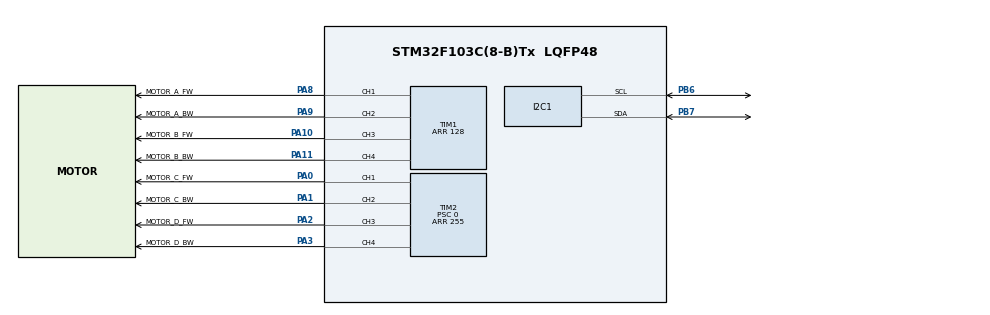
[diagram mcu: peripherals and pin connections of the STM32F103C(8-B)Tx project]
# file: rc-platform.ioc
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I2C1.GeneralCallMode=I2C_GENERALCALL_DISABLE
I2C1.OwnAddress=23
Mcu.Family=STM32F1
Mcu.Name=STM32F103C(8-B)Tx
Mcu.Package=LQFP48
NVIC.I2C1_EV_IRQn=true\:0\:0\:false\:false\:true\:true\:true\:true
NVIC.PriorityGroup=NVIC_PRIORITYGROUP_4
PA0-WKUP.GPIO_Label=MOTOR_C_FW
PA0-WKUP.Signal=S_TIM2_CH1_ETR
PA1.GPIO_Label=MOTOR_C_BW
PA1.Signal=S_TIM2_CH2
PA10.GPIO_Label=MOTOR_B_FW
PA10.Signal=S_TIM1_CH3
PA11.GPIO_Label=MOTOR_B_BW
PA11.Signal=S_TIM1_CH4
PA13.Mode=Serial_Wire
PA13.Signal=SYS_JTMS-SWDIO
PA14.Mode=Serial_Wire
PA14.Signal=SYS_JTCK-SWCLK
PA2.GPIO_Label=MOTOR_D_FW
PA2.Signal=S_TIM2_CH3
PA3.GPIO_Label=MOTOR_D_BW
PA3.Signal=S_TIM2_CH4
PA8.GPIO_Label=MOTOR_A_FW
PA8.Signal=S_TIM1_CH1
PA9.GPIO_Label=MOTOR_A_BW
PA9.Signal=S_TIM1_CH2
PB6.Mode=I2C
PB6.Signal=I2C1_SCL
PB7.Mode=I2C
PB7.Signal=I2C1_SDA
ProjectManager.HeapSize=0x200
ProjectManager.StackSize=0x400
ProjectManager.TargetToolchain=STM32CubeIDE
RCC.AHBFreq_Value=8000000
RCC.APB1Freq_Value=8000000
RCC.APB1TimFreq_Value=8000000
RCC.APB2Freq_Value=8000000
RCC.APB2TimFreq_Value=8000000
RCC.HCLKFreq_Value=8000000
SH.S_TIM1_CH1.0=TIM1_CH1,PWM Generation1 CH1
SH.S_TIM1_CH2.0=TIM1_CH2,PWM Generation2 CH2
SH.S_TIM1_CH3.0=TIM1_CH3,PWM Generation3 CH3
SH.S_TIM1_CH4.0=TIM1_CH4,PWM Generation4 CH4
SH.S_TIM2_CH1_ETR.0=TIM2_CH1,PWM Generation1 CH1
SH.S_TIM2_CH2.0=TIM2_CH2,PWM Generation2 CH2
SH.S_TIM2_CH3.0=TIM2_CH3,PWM Generation3 CH3
SH.S_TIM2_CH4.0=TIM2_CH4,PWM Generation4 CH4
TIM1.Channel-PWM\ Generation1\ CH1=TIM_CHANNEL_1
TIM1.Channel-PWM\ Generation2\ CH2=TIM_CHANNEL_2
TIM1.Channel-PWM\ Generation3\ CH3=TIM_CHANNEL_3
TIM1.Channel-PWM\ Generation4\ CH4=TIM_CHANNEL_4
TIM1.Period=128
TIM2.Channel-PWM\ Generation1\ CH1=TIM_CHANNEL_1
TIM2.Channel-PWM\ Generation2\ CH2=TIM_CHANNEL_2
TIM2.Channel-PWM\ Generation3\ CH3=TIM_CHANNEL_3
TIM2.Channel-PWM\ Generation4\ CH4=TIM_CHANNEL_4
TIM2.Period=255
TIM2.Prescaler=0
VP_TIM1_VS_ClockSourceINT.Mode=Internal
VP_TIM2_VS_ClockSourceINT.Mode=Internal
board=custom

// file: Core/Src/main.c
/* USER CODE BEGIN Header */
/**
  ******************************************************************************
  * @file           : main.c
  * @brief          : Main program body
  ******************************************************************************
  * @attention
  *
  * Copyright (c) 2025 STMicroelectronics.
  * All rights reserved.
  *
  * This software is licensed under terms that can be found in the LICENSE file
  * in the root directory of this software component.
  * If no LICENSE file comes with this software, it is provided AS-IS.
  *
  ******************************************************************************
  */
/* USER CODE END Header */
#include "main.h"
#include "i2c.h"
#include "tim.h"
#include "gpio.h"

/* USER CODE BEGIN Includes */
#include "rc_car.h"
/* USER CODE END Includes */

/* USER CODE BEGIN PV */

uint8_t i2c_buffer[4];
/* USER CODE END PV */

void SystemClock_Config(void);

/* USER CODE BEGIN 0 */
void HAL_I2C_SlaveRxCpltCallback(I2C_HandleTypeDef *hi2c)
{
	rc_car_SetMotorSpeed(&rc_car_motor_FrontLeft,  (int8_t)i2c_buffer[0]);
	rc_car_SetMotorSpeed(&rc_car_motor_FrontRight, (int8_t)i2c_buffer[1]);
	rc_car_SetMotorSpeed(&rc_car_motor_RearLeft,   (int8_t)i2c_buffer[2]);
	rc_car_SetMotorSpeed(&rc_car_motor_RearRight,  (int8_t)i2c_buffer[3]);

	HAL_I2C_Slave_Receive_IT(&hi2c1, i2c_buffer, sizeof(i2c_buffer));
}
/* USER CODE END 0 */

int main(void)
{

  /* MCU Configuration--------------------------------------------------------*/

  /* Reset of all peripherals, Initializes the Flash interface and the Systick. */
  HAL_Init();

  /* Configure the system clock */
  SystemClock_Config();

  /* Initialize all configured peripherals */
  MX_GPIO_Init();
  MX_I2C1_Init();
  MX_TIM1_Init();
  MX_TIM2_Init();
  /* USER CODE BEGIN 2 */

  rc_car_MotorsInit();

  // one signed byte per motor of our RC car.
  // this is where we receive our new speeds from our i2c master.

  HAL_I2C_Slave_Receive_IT(&hi2c1, i2c_buffer, sizeof(i2c_buffer));

  /* USER CODE END 2 */

  /* Infinite loop */
  while (1)
  {

  }
}

void SystemClock_Config(void)
{
  RCC_OscInitTypeDef RCC_OscInitStruct = {0};
  RCC_ClkInitTypeDef RCC_ClkInitStruct = {0};

  /** Initializes the RCC Oscillators according to the specified parameters
  * in the RCC_OscInitTypeDef structure.
  */
  RCC_OscInitStruct.OscillatorType = RCC_OSCILLATORTYPE_HSI;
  RCC_OscInitStruct.HSIState = RCC_HSI_ON;
  RCC_OscInitStruct.HSICalibrationValue = RCC_HSICALIBRATION_DEFAULT;
  RCC_OscInitStruct.PLL.PLLState = RCC_PLL_NONE;
  if (HAL_RCC_OscConfig(&RCC_OscInitStruct) != HAL_OK)
  {
    Error_Handler();
  }

  /** Initializes the CPU, AHB and APB buses clocks
  */
  RCC_ClkInitStruct.ClockType = RCC_CLOCKTYPE_HCLK|RCC_CLOCKTYPE_SYSCLK
                              |RCC_CLOCKTYPE_PCLK1|RCC_CLOCKTYPE_PCLK2;
  RCC_ClkInitStruct.SYSCLKSource = RCC_SYSCLKSOURCE_HSI;
  RCC_ClkInitStruct.AHBCLKDivider = RCC_SYSCLK_DIV1;
  RCC_ClkInitStruct.APB1CLKDivider = RCC_HCLK_DIV1;
  RCC_ClkInitStruct.APB2CLKDivider = RCC_HCLK_DIV1;

  if (HAL_RCC_ClockConfig(&RCC_ClkInitStruct, FLASH_LATENCY_0) != HAL_OK)
  {
    Error_Handler();
  }
}

void Error_Handler(void)
{
  __disable_irq();
  while (1)
  {
  }
}
